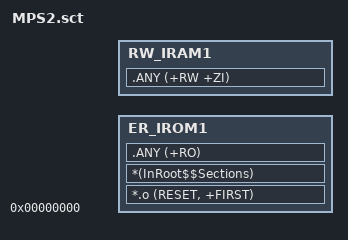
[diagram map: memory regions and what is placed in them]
; *************************************************************
; *** Scatter-Loading Description File                      ***
; *************************************************************

 LR_IROM1 0x00000000 0x00400000  {    ; load region size_region
   ER_IROM1 +0  {  ; load address = execution address
    *.o (RESET, +FIRST)
    *(InRoot$$Sections)
    .ANY (+RO)
   }
   RW_IRAM1 +0  {  ; RW data
    .ANY (+RW +ZI)
   }
 }

